# BGM11S22F256GA register map
File version: 4.0.0
CPU: CM4 r0p1, little endian, no MPU, no FPU, 0x3 interrupt priority bits, 0x0 interrupts
Registers are 32-bit, read-write, reset 0x0 unless marked. A register's access mark holds for its fields unless they carry their own. Offsets are from the block's base; [hi:lo] are bit positions.

## MSC
Base 0x400E0000
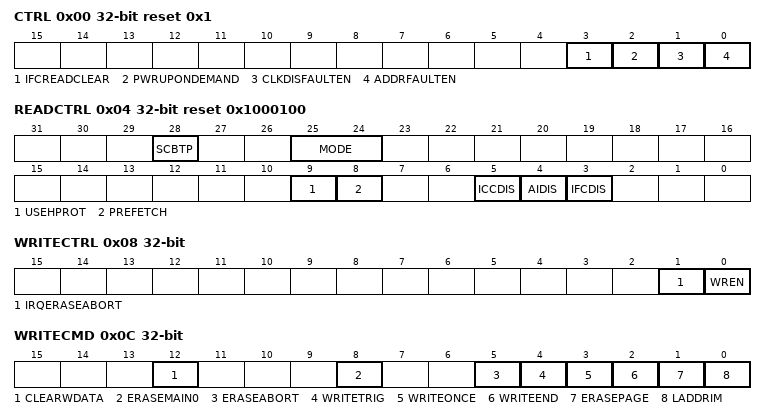
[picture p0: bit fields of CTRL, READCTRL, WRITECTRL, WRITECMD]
0x00 CTRL reset 0x1 — Memory System Control Register
  [3] IFCREADCLEAR — IFC Read Clears IF
  [2] PWRUPONDEMAND — Power Up on Demand During Wake Up
  [1] CLKDISFAULTEN — Clock-disabled Bus Fault Response Enable
  [0] ADDRFAULTEN — Invalid Address Bus Fault Response Enable
0x04 READCTRL reset 0x1000100 — Read Control Register
  [28] SCBTP — Suppress Conditional Branch Target Perfetch
  [25:24] MODE — Read Mode
    0=WS0 (Zero wait-states inserted in fetch or read transfers); 1=WS1 (One wait-state inserted for each fetch or read transfer. See Flash Wait-States table for details)
  [9] USEHPROT — AHB_HPROT Mode
  [8] PREFETCH — Prefetch Mode
  [5] ICCDIS — Interrupt Context Cache Disable
  [4] AIDIS — Automatic Invalidate Disable
  [3] IFCDIS — Internal Flash Cache Disable
0x08 WRITECTRL — Write Control Register
  [1] IRQERASEABORT — Abort Page Erase on Interrupt
  [0] WREN — Enable Write/Erase Controller
0x0C WRITECMD wo — Write Command Register
  [12] CLEARWDATA — Clear WDATA State
  [8] ERASEMAIN0 — Mass Erase Region 0
  [5] ERASEABORT — Abort Erase Sequence
  [4] WRITETRIG — Word Write Sequence Trigger
  [3] WRITEONCE — Word Write-Once Trigger
  [2] WRITEEND — End Write Mode
  [1] ERASEPAGE
  [0] LADDRIM — Load MSC_ADDRB Into ADDR
0x10 ADDRB — Page Erase/Write Address Buffer
  [31:0] ADDRB — Page Erase or Write Address Buffer
0x18 WDATA — Write Data Register
  [31:0] WDATA — Write Data
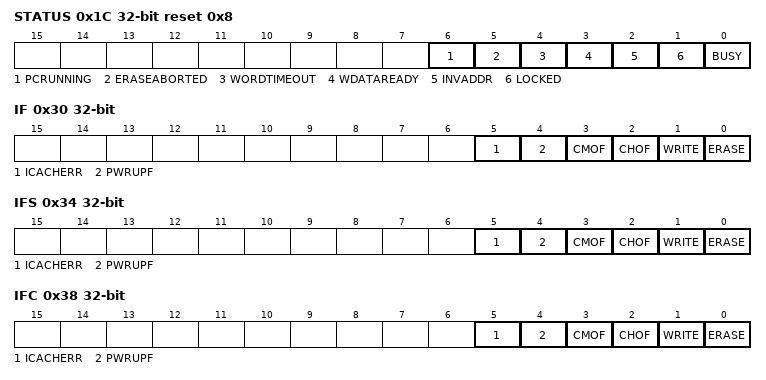
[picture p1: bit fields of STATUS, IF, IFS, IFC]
0x1C STATUS ro reset 0x8
  [6] PCRUNNING — Performance Counters Running
  [5] ERASEABORTED — The Current Flash Erase Operation Aborted
  [4] WORDTIMEOUT — Flash Write Word Timeout
  [3] WDATAREADY — WDATA Write Ready
  [2] INVADDR — Invalid Write Address or Erase Page
  [1] LOCKED — Access Locked
  [0] BUSY — Erase/Write Busy
0x30 IF ro — Interrupt Flag Register
  [5] ICACHERR — ICache RAM Parity Error Flag
  [4] PWRUPF — Flash Power Up Sequence Complete Flag
  [3] CMOF — Cache Misses Overflow Interrupt Flag
  [2] CHOF — Cache Hits Overflow Interrupt Flag
  [1] WRITE — Write Done Interrupt Read Flag
  [0] ERASE — Erase Done Interrupt Read Flag
0x34 IFS wo — Interrupt Flag Set Register
  [5] ICACHERR — Set ICACHERR Interrupt Flag
  [4] PWRUPF — Set PWRUPF Interrupt Flag
  [3] CMOF — Set CMOF Interrupt Flag
  [2] CHOF — Set CHOF Interrupt Flag
  [1] WRITE — Set WRITE Interrupt Flag
  [0] ERASE — Set ERASE Interrupt Flag
0x38 IFC wo — Interrupt Flag Clear Register
  [5] ICACHERR — Clear ICACHERR Interrupt Flag
  [4] PWRUPF — Clear PWRUPF Interrupt Flag
  [3] CMOF — Clear CMOF Interrupt Flag
  [2] CHOF — Clear CHOF Interrupt Flag
  [1] WRITE — Clear WRITE Interrupt Flag
  [0] ERASE — Clear ERASE Interrupt Flag
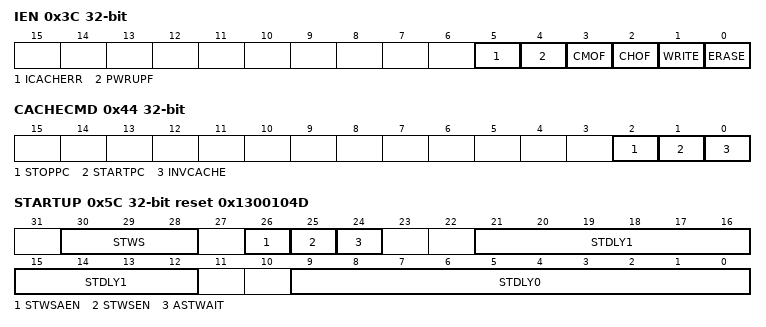
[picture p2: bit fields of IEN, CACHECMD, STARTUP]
0x3C IEN — Interrupt Enable Register
  [5] ICACHERR — ICACHERR Interrupt Enable
  [4] PWRUPF — PWRUPF Interrupt Enable
  [3] CMOF — CMOF Interrupt Enable
  [2] CHOF — CHOF Interrupt Enable
  [1] WRITE — WRITE Interrupt Enable
  [0] ERASE — ERASE Interrupt Enable
0x40 LOCK — Configuration Lock Register
  [15:0] LOCKKEY — Configuration Lock
    0=UNLOCKED; 1=LOCKED
0x44 CACHECMD wo — Flash Cache Command Register
  [2] STOPPC — Stop Performance Counters
  [1] STARTPC — Start Performance Counters
  [0] INVCACHE — Invalidate Instruction Cache
0x48 CACHEHITS ro — Cache Hits Performance Counter
  [19:0] CACHEHITS — Cache Hits Since Last Performance Counter Start Command
0x4C CACHEMISSES ro — Cache Misses Performance Counter
  [19:0] CACHEMISSES — Cache Misses Since Last Performance Counter Start Command
0x54 MASSLOCK reset 0x1 — Mass Erase Lock Register
  [15:0] LOCKKEY — Mass Erase Lock
    0=UNLOCKED; 1=LOCKED
0x5C STARTUP reset 0x1300104D — Startup Control
  [30:28] STWS — Startup Waitstates
  [26] STWSAEN — Startup Waitstates Always Enable
  [25] STWSEN — Startup Waitstates Enable
  [24] ASTWAIT — Active Startup Wait
  [21:12] STDLY1 — Startup Delay 0
  [9:0] STDLY0 — Startup Delay 0
0x74 CMD wo — Command Register
  [0] PWRUP — Flash Power Up Command
